# VPAC0_CP_INTD_CFG_INTD_CFG register map
Vendor: Texas Instruments
Registers are 32-bit, access not given, reset 0x0 unless marked. A register's access mark holds for its fields unless they carry their own. Offsets are as the file gives them; [hi:lo] are bit positions; {n}, {i} and the like mark numbered series.

## VPAC0_CP_INTD_CFG_INTD_CFG (part 2 of 2)
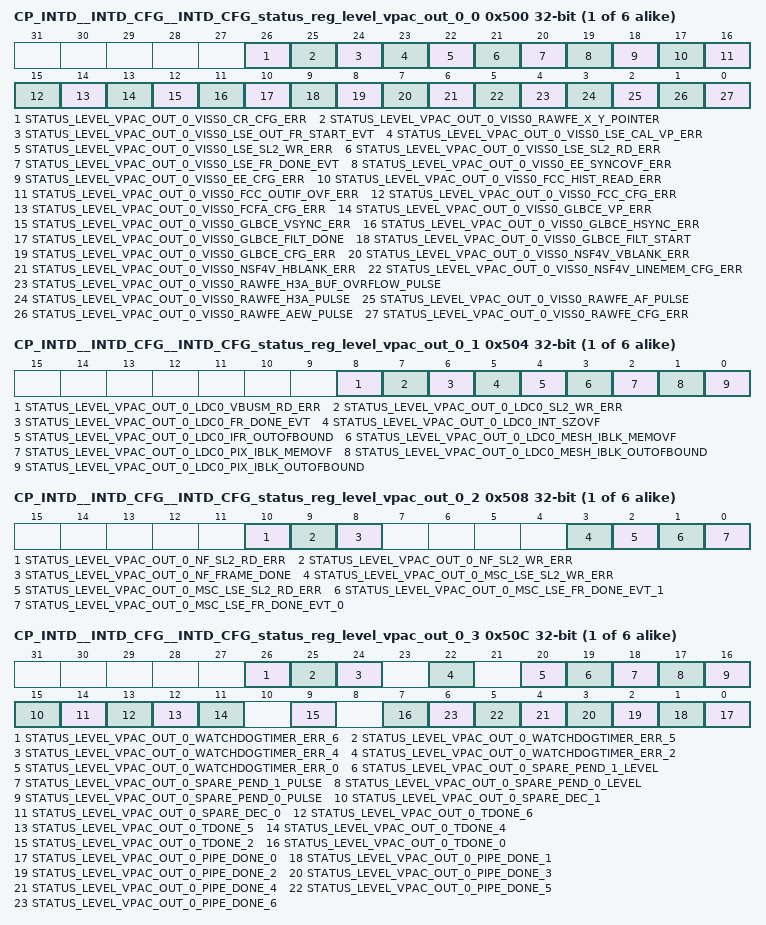
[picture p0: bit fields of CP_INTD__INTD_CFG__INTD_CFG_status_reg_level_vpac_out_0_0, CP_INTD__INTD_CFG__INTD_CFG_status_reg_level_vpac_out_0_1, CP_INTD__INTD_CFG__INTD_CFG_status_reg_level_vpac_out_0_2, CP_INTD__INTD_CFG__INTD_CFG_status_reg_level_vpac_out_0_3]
{0x500+0x20*i} CP_INTD__INTD_CFG__INTD_CFG_status_reg_level_vpac_out_{i}_0 (i=0..5) — Status Register {8i}
  [26] STATUS_LEVEL_VPAC_OUT_{i}_VISS0_CR_CFG_ERR — Status ,write 1 to set, for level_vpac_out_{i}_en_viss0_cr_cfg_err (access R/W1TS)
  [25] STATUS_LEVEL_VPAC_OUT_{i}_VISS0_RAWFE_X_Y_POINTER — Status ,write 1 to set, for level_vpac_out_{i}_en_viss0_rawfe_x_y_pointer (access R/W1TS)
  [24] STATUS_LEVEL_VPAC_OUT_{i}_VISS0_LSE_OUT_FR_START_EVT — Status ,write 1 to set, for level_vpac_out_{i}_en_viss0_lse_out_fr_start_evt (access R/W1TS)
  [23] STATUS_LEVEL_VPAC_OUT_{i}_VISS0_LSE_CAL_VP_ERR — Status ,write 1 to set, for level_vpac_out_{i}_en_viss0_lse_cal_vp_err (access R/W1TS)
  [22] STATUS_LEVEL_VPAC_OUT_{i}_VISS0_LSE_SL2_WR_ERR — Status ,write 1 to set, for level_vpac_out_{i}_en_viss0_lse_sl2_wr_err (access R/W1TS)
  [21] STATUS_LEVEL_VPAC_OUT_{i}_VISS0_LSE_SL2_RD_ERR — Status ,write 1 to set, for level_vpac_out_{i}_en_viss0_lse_sl2_rd_err (access R/W1TS)
  [20] STATUS_LEVEL_VPAC_OUT_{i}_VISS0_LSE_FR_DONE_EVT — Status ,write 1 to set, for level_vpac_out_{i}_en_viss0_lse_fr_done_evt (access R/W1TS)
  [19] STATUS_LEVEL_VPAC_OUT_{i}_VISS0_EE_SYNCOVF_ERR — Status ,write 1 to set, for level_vpac_out_{i}_en_viss0_ee_syncovf_err (access R/W1TS)
  [18] STATUS_LEVEL_VPAC_OUT_{i}_VISS0_EE_CFG_ERR — Status ,write 1 to set, for level_vpac_out_{i}_en_viss0_ee_cfg_err (access R/W1TS)
  [17] STATUS_LEVEL_VPAC_OUT_{i}_VISS0_FCC_HIST_READ_ERR — Status ,write 1 to set, for level_vpac_out_{i}_en_viss0_fcc_hist_read_err (access R/W1TS)
  [16] STATUS_LEVEL_VPAC_OUT_{i}_VISS0_FCC_OUTIF_OVF_ERR — Status ,write 1 to set, for level_vpac_out_{i}_en_viss0_fcc_outif_ovf_err (access R/W1TS)
  [15] STATUS_LEVEL_VPAC_OUT_{i}_VISS0_FCC_CFG_ERR — Status ,write 1 to set, for level_vpac_out_{i}_en_viss0_fcc_cfg_err (access R/W1TS)
  [14] STATUS_LEVEL_VPAC_OUT_{i}_VISS0_FCFA_CFG_ERR — Status ,write 1 to set, for level_vpac_out_{i}_en_viss0_fcfa_cfg_err (access R/W1TS)
  [13] STATUS_LEVEL_VPAC_OUT_{i}_VISS0_GLBCE_VP_ERR — Status ,write 1 to set, for level_vpac_out_{i}_en_viss0_glbce_vp_err (access R/W1TS)
  [12] STATUS_LEVEL_VPAC_OUT_{i}_VISS0_GLBCE_VSYNC_ERR — Status ,write 1 to set, for level_vpac_out_{i}_en_viss0_glbce_vsync_err (access R/W1TS)
  [11] STATUS_LEVEL_VPAC_OUT_{i}_VISS0_GLBCE_HSYNC_ERR — Status ,write 1 to set, for level_vpac_out_{i}_en_viss0_glbce_hsync_err (access R/W1TS)
  [10] STATUS_LEVEL_VPAC_OUT_{i}_VISS0_GLBCE_FILT_DONE — Status ,write 1 to set, for level_vpac_out_{i}_en_viss0_glbce_filt_done (access R/W1TS)
  [9] STATUS_LEVEL_VPAC_OUT_{i}_VISS0_GLBCE_FILT_START — Status ,write 1 to set, for level_vpac_out_{i}_en_viss0_glbce_filt_start (access R/W1TS)
  [8] STATUS_LEVEL_VPAC_OUT_{i}_VISS0_GLBCE_CFG_ERR — Status ,write 1 to set, for level_vpac_out_{i}_en_viss0_glbce_cfg_err (access R/W1TS)
  [7] STATUS_LEVEL_VPAC_OUT_{i}_VISS0_NSF4V_VBLANK_ERR — Status ,write 1 to set, for level_vpac_out_{i}_en_viss0_nsf4v_vblank_err (access R/W1TS)
  [6] STATUS_LEVEL_VPAC_OUT_{i}_VISS0_NSF4V_HBLANK_ERR — Status ,write 1 to set, for level_vpac_out_{i}_en_viss0_nsf4v_hblank_err (access R/W1TS)
  [5] STATUS_LEVEL_VPAC_OUT_{i}_VISS0_NSF4V_LINEMEM_CFG_ERR — Status ,write 1 to set, for level_vpac_out_{i}_en_viss0_nsf4v_linemem_cfg_err (access R/W1TS)
  [4] STATUS_LEVEL_VPAC_OUT_{i}_VISS0_RAWFE_H3A_BUF_OVRFLOW_PULSE — Status ,write 1 to set, for level_vpac_out_{i}_en_viss0_rawfe_h3a_buf_ovrflow_pulse (access R/W1TS)
  [3] STATUS_LEVEL_VPAC_OUT_{i}_VISS0_RAWFE_H3A_PULSE — Status ,write 1 to set, for level_vpac_out_{i}_en_viss0_rawfe_h3a_pulse (access R/W1TS)
  [2] STATUS_LEVEL_VPAC_OUT_{i}_VISS0_RAWFE_AF_PULSE — Status ,write 1 to set, for level_vpac_out_{i}_en_viss0_rawfe_af_pulse (access R/W1TS)
  [1] STATUS_LEVEL_VPAC_OUT_{i}_VISS0_RAWFE_AEW_PULSE — Status ,write 1 to set, for level_vpac_out_{i}_en_viss0_rawfe_aew_pulse (access R/W1TS)
  [0] STATUS_LEVEL_VPAC_OUT_{i}_VISS0_RAWFE_CFG_ERR — Status ,write 1 to set, for level_vpac_out_{i}_en_viss0_rawfe_cfg_err (access R/W1TS)
{0x504+0x20*i} CP_INTD__INTD_CFG__INTD_CFG_status_reg_level_vpac_out_{i}_1 (i=0..5) — Status Register {8i+1}
  [8] STATUS_LEVEL_VPAC_OUT_{i}_LDC0_VBUSM_RD_ERR — Status ,write 1 to set, for level_vpac_out_{i}_en_ldc0_vbusm_rd_err (access R/W1TS)
  [7] STATUS_LEVEL_VPAC_OUT_{i}_LDC0_SL2_WR_ERR — Status ,write 1 to set, for level_vpac_out_{i}_en_ldc0_sl2_wr_err (access R/W1TS)
  [6] STATUS_LEVEL_VPAC_OUT_{i}_LDC0_FR_DONE_EVT — Status ,write 1 to set, for level_vpac_out_{i}_en_ldc0_fr_done_evt (access R/W1TS)
  [5] STATUS_LEVEL_VPAC_OUT_{i}_LDC0_INT_SZOVF — Status ,write 1 to set, for level_vpac_out_{i}_en_ldc0_int_szovf (access R/W1TS)
  [4] STATUS_LEVEL_VPAC_OUT_{i}_LDC0_IFR_OUTOFBOUND — Status ,write 1 to set, for level_vpac_out_{i}_en_ldc0_ifr_outofbound (access R/W1TS)
  [3] STATUS_LEVEL_VPAC_OUT_{i}_LDC0_MESH_IBLK_MEMOVF — Status ,write 1 to set, for level_vpac_out_{i}_en_ldc0_mesh_iblk_memovf (access R/W1TS)
  [2] STATUS_LEVEL_VPAC_OUT_{i}_LDC0_PIX_IBLK_MEMOVF — Status ,write 1 to set, for level_vpac_out_{i}_en_ldc0_pix_iblk_memovf (access R/W1TS)
  [1] STATUS_LEVEL_VPAC_OUT_{i}_LDC0_MESH_IBLK_OUTOFBOUND — Status ,write 1 to set, for level_vpac_out_{i}_en_ldc0_mesh_iblk_outofbound (access R/W1TS)
  [0] STATUS_LEVEL_VPAC_OUT_{i}_LDC0_PIX_IBLK_OUTOFBOUND — Status ,write 1 to set, for level_vpac_out_{i}_en_ldc0_pix_iblk_outofbound (access R/W1TS)
{0x508+0x20*i} CP_INTD__INTD_CFG__INTD_CFG_status_reg_level_vpac_out_{i}_2 (i=0..5) — Status Register {8i+2}
  [10] STATUS_LEVEL_VPAC_OUT_{i}_NF_SL2_RD_ERR — Status ,write 1 to set, for level_vpac_out_{i}_en_nf_sl2_rd_err (access R/W1TS)
  [9] STATUS_LEVEL_VPAC_OUT_{i}_NF_SL2_WR_ERR — Status ,write 1 to set, for level_vpac_out_{i}_en_nf_sl2_wr_err (access R/W1TS)
  [8] STATUS_LEVEL_VPAC_OUT_{i}_NF_FRAME_DONE — Status ,write 1 to set, for level_vpac_out_{i}_en_nf_frame_done (access R/W1TS)
  [3] STATUS_LEVEL_VPAC_OUT_{i}_MSC_LSE_SL2_WR_ERR — Status ,write 1 to set, for level_vpac_out_{i}_en_msc_lse_sl2_wr_err (access R/W1TS)
  [2] STATUS_LEVEL_VPAC_OUT_{i}_MSC_LSE_SL2_RD_ERR — Status ,write 1 to set, for level_vpac_out_{i}_en_msc_lse_sl2_rd_err (access R/W1TS)
  [1] STATUS_LEVEL_VPAC_OUT_{i}_MSC_LSE_FR_DONE_EVT_1 — Status ,write 1 to set, for level_vpac_out_{i}_en_msc_lse_fr_done_evt_1 (access R/W1TS)
  [0] STATUS_LEVEL_VPAC_OUT_{i}_MSC_LSE_FR_DONE_EVT_0 — Status ,write 1 to set, for level_vpac_out_{i}_en_msc_lse_fr_done_evt_0 (access R/W1TS)
{0x50C+0x20*i} CP_INTD__INTD_CFG__INTD_CFG_status_reg_level_vpac_out_{i}_3 (i=0..5) — Status Register {8i+3}
  [26] STATUS_LEVEL_VPAC_OUT_{i}_WATCHDOGTIMER_ERR_6 — Status ,write 1 to set, for level_vpac_out_{i}_en_watchdogtimer_err_6 (access R/W1TS)
  [25] STATUS_LEVEL_VPAC_OUT_{i}_WATCHDOGTIMER_ERR_5 — Status ,write 1 to set, for level_vpac_out_{i}_en_watchdogtimer_err_5 (access R/W1TS)
  [24] STATUS_LEVEL_VPAC_OUT_{i}_WATCHDOGTIMER_ERR_4 — Status ,write 1 to set, for level_vpac_out_{i}_en_watchdogtimer_err_4 (access R/W1TS)
  [22] STATUS_LEVEL_VPAC_OUT_{i}_WATCHDOGTIMER_ERR_2 — Status ,write 1 to set, for level_vpac_out_{i}_en_watchdogtimer_err_2 (access R/W1TS)
  [20] STATUS_LEVEL_VPAC_OUT_{i}_WATCHDOGTIMER_ERR_0 — Status ,write 1 to set, for level_vpac_out_{i}_en_watchdogtimer_err_0 (access R/W1TS)
  [19] STATUS_LEVEL_VPAC_OUT_{i}_SPARE_PEND_1_LEVEL ro — Status for level_vpac_out_{i}_en_spare_pend_1_level
  [18] STATUS_LEVEL_VPAC_OUT_{i}_SPARE_PEND_1_PULSE ro — Status for level_vpac_out_{i}_en_spare_pend_1_pulse
  [17] STATUS_LEVEL_VPAC_OUT_{i}_SPARE_PEND_0_LEVEL ro — Status for level_vpac_out_{i}_en_spare_pend_0_level
  [16] STATUS_LEVEL_VPAC_OUT_{i}_SPARE_PEND_0_PULSE ro — Status for level_vpac_out_{i}_en_spare_pend_0_pulse
  [15] STATUS_LEVEL_VPAC_OUT_{i}_SPARE_DEC_1 — Status ,write 1 to set, for level_vpac_out_{i}_en_spare_dec_1 (access R/W1TS)
  [14] STATUS_LEVEL_VPAC_OUT_{i}_SPARE_DEC_0 — Status ,write 1 to set, for level_vpac_out_{i}_en_spare_dec_0 (access R/W1TS)
  [13] STATUS_LEVEL_VPAC_OUT_{i}_TDONE_6 — Status ,write 1 to set, for level_vpac_out_{i}_en_tdone_6 (access R/W1TS)
  [12] STATUS_LEVEL_VPAC_OUT_{i}_TDONE_5 — Status ,write 1 to set, for level_vpac_out_{i}_en_tdone_5 (access R/W1TS)
  [11] STATUS_LEVEL_VPAC_OUT_{i}_TDONE_4 — Status ,write 1 to set, for level_vpac_out_{i}_en_tdone_4 (access R/W1TS)
  [9] STATUS_LEVEL_VPAC_OUT_{i}_TDONE_2 — Status ,write 1 to set, for level_vpac_out_{i}_en_tdone_2 (access R/W1TS)
  [7] STATUS_LEVEL_VPAC_OUT_{i}_TDONE_0 — Status ,write 1 to set, for level_vpac_out_{i}_en_tdone_0 (access R/W1TS)
  [n] STATUS_LEVEL_VPAC_OUT_{i}_PIPE_DONE_{n} (n=0..6) — Status ,write 1 to set, for level_vpac_out_{i}_en_pipe_done_{n} (access R/W1TS)
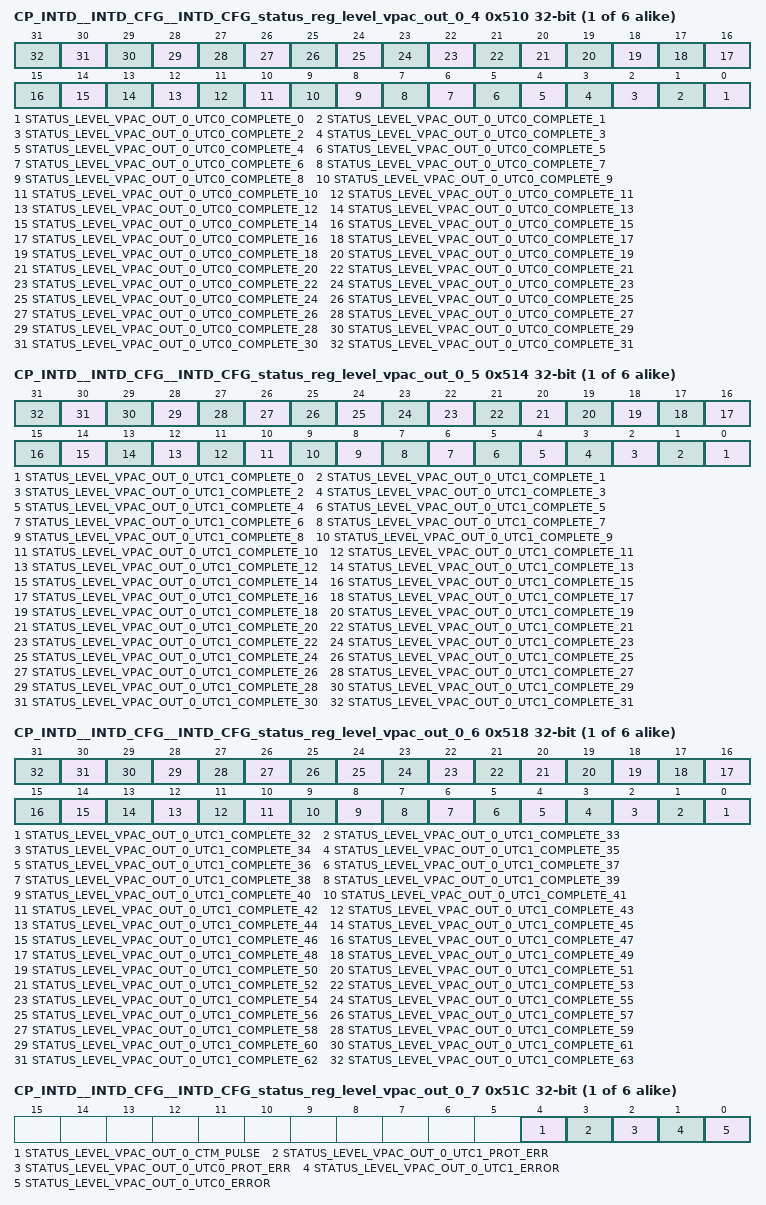
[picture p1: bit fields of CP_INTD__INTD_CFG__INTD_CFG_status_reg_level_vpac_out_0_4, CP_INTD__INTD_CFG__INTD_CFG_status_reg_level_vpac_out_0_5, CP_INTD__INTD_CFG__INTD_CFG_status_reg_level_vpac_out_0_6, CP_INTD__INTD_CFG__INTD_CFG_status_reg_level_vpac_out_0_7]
{0x510+0x20*i} CP_INTD__INTD_CFG__INTD_CFG_status_reg_level_vpac_out_{i}_4 (i=0..5) — Status Register {8i+4}
  [n] STATUS_LEVEL_VPAC_OUT_{i}_UTC0_COMPLETE_{n} (n=0..31) — Status ,write 1 to set, for level_vpac_out_{i}_en_utc0_complete_{n} (access R/W1TS)
{0x514+0x20*i} CP_INTD__INTD_CFG__INTD_CFG_status_reg_level_vpac_out_{i}_5 (i=0..5) — Status Register {8i+5}
  [n] STATUS_LEVEL_VPAC_OUT_{i}_UTC1_COMPLETE_{n} (n=0..31) — Status ,write 1 to set, for level_vpac_out_{i}_en_utc1_complete_{n} (access R/W1TS)
{0x518+0x20*i} CP_INTD__INTD_CFG__INTD_CFG_status_reg_level_vpac_out_{i}_6 (i=0..5) — Status Register {8i+6}
  [n-32] STATUS_LEVEL_VPAC_OUT_{i}_UTC1_COMPLETE_{n} (n=32..63) — Status ,write 1 to set, for level_vpac_out_{i}_en_utc1_complete_{n} (access R/W1TS)
{0x51C+0x20*i} CP_INTD__INTD_CFG__INTD_CFG_status_reg_level_vpac_out_{i}_7 (i=0..5) — Status Register {8i+7}
  [4] STATUS_LEVEL_VPAC_OUT_{i}_CTM_PULSE — Status ,write 1 to set, for level_vpac_out_{i}_en_ctm_pulse (access R/W1TS)
  [3] STATUS_LEVEL_VPAC_OUT_{i}_UTC1_PROT_ERR — Status ,write 1 to set, for level_vpac_out_{i}_en_utc1_prot_err (access R/W1TS)
  [2] STATUS_LEVEL_VPAC_OUT_{i}_UTC0_PROT_ERR — Status ,write 1 to set, for level_vpac_out_{i}_en_utc0_prot_err (access R/W1TS)
  [1] STATUS_LEVEL_VPAC_OUT_{i}_UTC1_ERROR — Status ,write 1 to set, for level_vpac_out_{i}_en_utc1_error (access R/W1TS)
  [0] STATUS_LEVEL_VPAC_OUT_{i}_UTC0_ERROR — Status ,write 1 to set, for level_vpac_out_{i}_en_utc0_error (access R/W1TS)
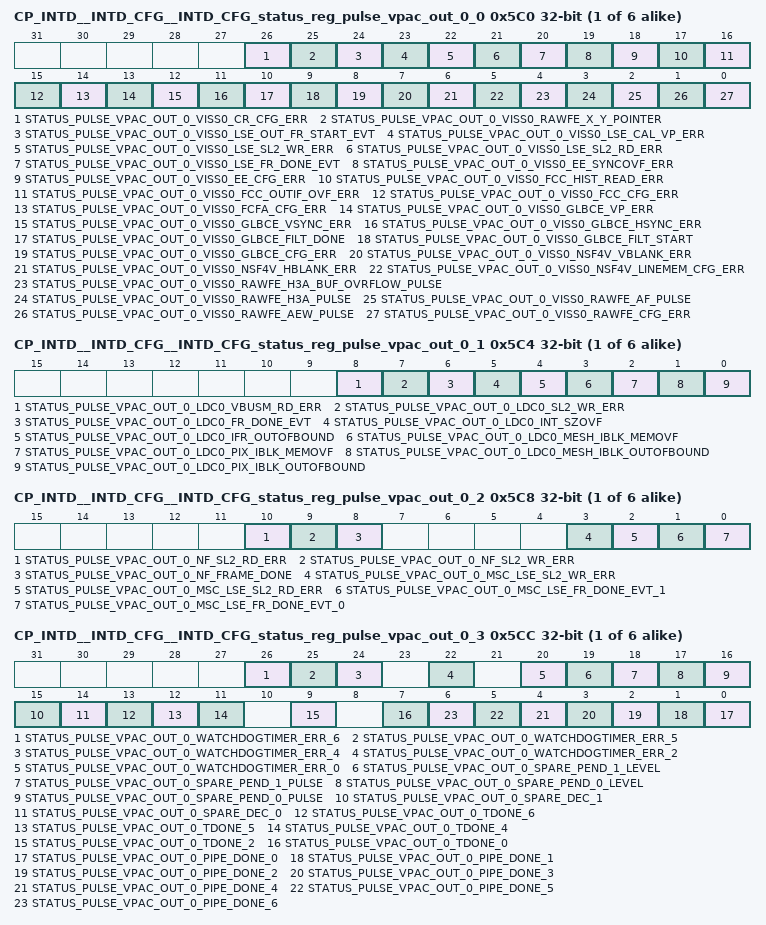
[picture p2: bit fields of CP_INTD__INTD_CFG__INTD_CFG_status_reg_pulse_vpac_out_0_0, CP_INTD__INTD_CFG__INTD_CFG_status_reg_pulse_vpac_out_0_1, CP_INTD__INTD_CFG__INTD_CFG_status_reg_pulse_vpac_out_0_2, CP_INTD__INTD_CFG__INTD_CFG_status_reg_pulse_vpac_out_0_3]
{0x5C0+0x20*i} CP_INTD__INTD_CFG__INTD_CFG_status_reg_pulse_vpac_out_{i}_0 (i=0..5) — Status Register {8i+48}
  [26] STATUS_PULSE_VPAC_OUT_{i}_VISS0_CR_CFG_ERR — Status ,write 1 to set, for pulse_vpac_out_{i}_en_viss0_cr_cfg_err (access R/W1TS)
  [25] STATUS_PULSE_VPAC_OUT_{i}_VISS0_RAWFE_X_Y_POINTER — Status ,write 1 to set, for pulse_vpac_out_{i}_en_viss0_rawfe_x_y_pointer (access R/W1TS)
  [24] STATUS_PULSE_VPAC_OUT_{i}_VISS0_LSE_OUT_FR_START_EVT — Status ,write 1 to set, for pulse_vpac_out_{i}_en_viss0_lse_out_fr_start_evt (access R/W1TS)
  [23] STATUS_PULSE_VPAC_OUT_{i}_VISS0_LSE_CAL_VP_ERR — Status ,write 1 to set, for pulse_vpac_out_{i}_en_viss0_lse_cal_vp_err (access R/W1TS)
  [22] STATUS_PULSE_VPAC_OUT_{i}_VISS0_LSE_SL2_WR_ERR — Status ,write 1 to set, for pulse_vpac_out_{i}_en_viss0_lse_sl2_wr_err (access R/W1TS)
  [21] STATUS_PULSE_VPAC_OUT_{i}_VISS0_LSE_SL2_RD_ERR — Status ,write 1 to set, for pulse_vpac_out_{i}_en_viss0_lse_sl2_rd_err (access R/W1TS)
  [20] STATUS_PULSE_VPAC_OUT_{i}_VISS0_LSE_FR_DONE_EVT — Status ,write 1 to set, for pulse_vpac_out_{i}_en_viss0_lse_fr_done_evt (access R/W1TS)
  [19] STATUS_PULSE_VPAC_OUT_{i}_VISS0_EE_SYNCOVF_ERR — Status ,write 1 to set, for pulse_vpac_out_{i}_en_viss0_ee_syncovf_err (access R/W1TS)
  [18] STATUS_PULSE_VPAC_OUT_{i}_VISS0_EE_CFG_ERR — Status ,write 1 to set, for pulse_vpac_out_{i}_en_viss0_ee_cfg_err (access R/W1TS)
  [17] STATUS_PULSE_VPAC_OUT_{i}_VISS0_FCC_HIST_READ_ERR — Status ,write 1 to set, for pulse_vpac_out_{i}_en_viss0_fcc_hist_read_err (access R/W1TS)
  [16] STATUS_PULSE_VPAC_OUT_{i}_VISS0_FCC_OUTIF_OVF_ERR — Status ,write 1 to set, for pulse_vpac_out_{i}_en_viss0_fcc_outif_ovf_err (access R/W1TS)
  [15] STATUS_PULSE_VPAC_OUT_{i}_VISS0_FCC_CFG_ERR — Status ,write 1 to set, for pulse_vpac_out_{i}_en_viss0_fcc_cfg_err (access R/W1TS)
  [14] STATUS_PULSE_VPAC_OUT_{i}_VISS0_FCFA_CFG_ERR — Status ,write 1 to set, for pulse_vpac_out_{i}_en_viss0_fcfa_cfg_err (access R/W1TS)
  [13] STATUS_PULSE_VPAC_OUT_{i}_VISS0_GLBCE_VP_ERR — Status ,write 1 to set, for pulse_vpac_out_{i}_en_viss0_glbce_vp_err (access R/W1TS)
  [12] STATUS_PULSE_VPAC_OUT_{i}_VISS0_GLBCE_VSYNC_ERR — Status ,write 1 to set, for pulse_vpac_out_{i}_en_viss0_glbce_vsync_err (access R/W1TS)
  [11] STATUS_PULSE_VPAC_OUT_{i}_VISS0_GLBCE_HSYNC_ERR — Status ,write 1 to set, for pulse_vpac_out_{i}_en_viss0_glbce_hsync_err (access R/W1TS)
  [10] STATUS_PULSE_VPAC_OUT_{i}_VISS0_GLBCE_FILT_DONE — Status ,write 1 to set, for pulse_vpac_out_{i}_en_viss0_glbce_filt_done (access R/W1TS)
  [9] STATUS_PULSE_VPAC_OUT_{i}_VISS0_GLBCE_FILT_START — Status ,write 1 to set, for pulse_vpac_out_{i}_en_viss0_glbce_filt_start (access R/W1TS)
  [8] STATUS_PULSE_VPAC_OUT_{i}_VISS0_GLBCE_CFG_ERR — Status ,write 1 to set, for pulse_vpac_out_{i}_en_viss0_glbce_cfg_err (access R/W1TS)
  [7] STATUS_PULSE_VPAC_OUT_{i}_VISS0_NSF4V_VBLANK_ERR — Status ,write 1 to set, for pulse_vpac_out_{i}_en_viss0_nsf4v_vblank_err (access R/W1TS)
  [6] STATUS_PULSE_VPAC_OUT_{i}_VISS0_NSF4V_HBLANK_ERR — Status ,write 1 to set, for pulse_vpac_out_{i}_en_viss0_nsf4v_hblank_err (access R/W1TS)
  [5] STATUS_PULSE_VPAC_OUT_{i}_VISS0_NSF4V_LINEMEM_CFG_ERR — Status ,write 1 to set, for pulse_vpac_out_{i}_en_viss0_nsf4v_linemem_cfg_err (access R/W1TS)
  [4] STATUS_PULSE_VPAC_OUT_{i}_VISS0_RAWFE_H3A_BUF_OVRFLOW_PULSE — Status ,write 1 to set, for pulse_vpac_out_{i}_en_viss0_rawfe_h3a_buf_ovrflow_pulse (access R/W1TS)
  [3] STATUS_PULSE_VPAC_OUT_{i}_VISS0_RAWFE_H3A_PULSE — Status ,write 1 to set, for pulse_vpac_out_{i}_en_viss0_rawfe_h3a_pulse (access R/W1TS)
  [2] STATUS_PULSE_VPAC_OUT_{i}_VISS0_RAWFE_AF_PULSE — Status ,write 1 to set, for pulse_vpac_out_{i}_en_viss0_rawfe_af_pulse (access R/W1TS)
  [1] STATUS_PULSE_VPAC_OUT_{i}_VISS0_RAWFE_AEW_PULSE — Status ,write 1 to set, for pulse_vpac_out_{i}_en_viss0_rawfe_aew_pulse (access R/W1TS)
  [0] STATUS_PULSE_VPAC_OUT_{i}_VISS0_RAWFE_CFG_ERR — Status ,write 1 to set, for pulse_vpac_out_{i}_en_viss0_rawfe_cfg_err (access R/W1TS)
{0x5C4+0x20*i} CP_INTD__INTD_CFG__INTD_CFG_status_reg_pulse_vpac_out_{i}_1 (i=0..5) — Status Register {8i+49}
  [8] STATUS_PULSE_VPAC_OUT_{i}_LDC0_VBUSM_RD_ERR — Status ,write 1 to set, for pulse_vpac_out_{i}_en_ldc0_vbusm_rd_err (access R/W1TS)
  [7] STATUS_PULSE_VPAC_OUT_{i}_LDC0_SL2_WR_ERR — Status ,write 1 to set, for pulse_vpac_out_{i}_en_ldc0_sl2_wr_err (access R/W1TS)
  [6] STATUS_PULSE_VPAC_OUT_{i}_LDC0_FR_DONE_EVT — Status ,write 1 to set, for pulse_vpac_out_{i}_en_ldc0_fr_done_evt (access R/W1TS)
  [5] STATUS_PULSE_VPAC_OUT_{i}_LDC0_INT_SZOVF — Status ,write 1 to set, for pulse_vpac_out_{i}_en_ldc0_int_szovf (access R/W1TS)
  [4] STATUS_PULSE_VPAC_OUT_{i}_LDC0_IFR_OUTOFBOUND — Status ,write 1 to set, for pulse_vpac_out_{i}_en_ldc0_ifr_outofbound (access R/W1TS)
  [3] STATUS_PULSE_VPAC_OUT_{i}_LDC0_MESH_IBLK_MEMOVF — Status ,write 1 to set, for pulse_vpac_out_{i}_en_ldc0_mesh_iblk_memovf (access R/W1TS)
  [2] STATUS_PULSE_VPAC_OUT_{i}_LDC0_PIX_IBLK_MEMOVF — Status ,write 1 to set, for pulse_vpac_out_{i}_en_ldc0_pix_iblk_memovf (access R/W1TS)
  [1] STATUS_PULSE_VPAC_OUT_{i}_LDC0_MESH_IBLK_OUTOFBOUND — Status ,write 1 to set, for pulse_vpac_out_{i}_en_ldc0_mesh_iblk_outofbound (access R/W1TS)
  [0] STATUS_PULSE_VPAC_OUT_{i}_LDC0_PIX_IBLK_OUTOFBOUND — Status ,write 1 to set, for pulse_vpac_out_{i}_en_ldc0_pix_iblk_outofbound (access R/W1TS)
{0x5C8+0x20*i} CP_INTD__INTD_CFG__INTD_CFG_status_reg_pulse_vpac_out_{i}_2 (i=0..5) — Status Register {8i+50}
  [10] STATUS_PULSE_VPAC_OUT_{i}_NF_SL2_RD_ERR — Status ,write 1 to set, for pulse_vpac_out_{i}_en_nf_sl2_rd_err (access R/W1TS)
  [9] STATUS_PULSE_VPAC_OUT_{i}_NF_SL2_WR_ERR — Status ,write 1 to set, for pulse_vpac_out_{i}_en_nf_sl2_wr_err (access R/W1TS)
  [8] STATUS_PULSE_VPAC_OUT_{i}_NF_FRAME_DONE — Status ,write 1 to set, for pulse_vpac_out_{i}_en_nf_frame_done (access R/W1TS)
  [3] STATUS_PULSE_VPAC_OUT_{i}_MSC_LSE_SL2_WR_ERR — Status ,write 1 to set, for pulse_vpac_out_{i}_en_msc_lse_sl2_wr_err (access R/W1TS)
  [2] STATUS_PULSE_VPAC_OUT_{i}_MSC_LSE_SL2_RD_ERR — Status ,write 1 to set, for pulse_vpac_out_{i}_en_msc_lse_sl2_rd_err (access R/W1TS)
  [1] STATUS_PULSE_VPAC_OUT_{i}_MSC_LSE_FR_DONE_EVT_1 — Status ,write 1 to set, for pulse_vpac_out_{i}_en_msc_lse_fr_done_evt_1 (access R/W1TS)
  [0] STATUS_PULSE_VPAC_OUT_{i}_MSC_LSE_FR_DONE_EVT_0 — Status ,write 1 to set, for pulse_vpac_out_{i}_en_msc_lse_fr_done_evt_0 (access R/W1TS)
{0x5CC+0x20*i} CP_INTD__INTD_CFG__INTD_CFG_status_reg_pulse_vpac_out_{i}_3 (i=0..5) — Status Register {8i+51}
  [26] STATUS_PULSE_VPAC_OUT_{i}_WATCHDOGTIMER_ERR_6 — Status ,write 1 to set, for pulse_vpac_out_{i}_en_watchdogtimer_err_6 (access R/W1TS)
  [25] STATUS_PULSE_VPAC_OUT_{i}_WATCHDOGTIMER_ERR_5 — Status ,write 1 to set, for pulse_vpac_out_{i}_en_watchdogtimer_err_5 (access R/W1TS)
  [24] STATUS_PULSE_VPAC_OUT_{i}_WATCHDOGTIMER_ERR_4 — Status ,write 1 to set, for pulse_vpac_out_{i}_en_watchdogtimer_err_4 (access R/W1TS)
  [22] STATUS_PULSE_VPAC_OUT_{i}_WATCHDOGTIMER_ERR_2 — Status ,write 1 to set, for pulse_vpac_out_{i}_en_watchdogtimer_err_2 (access R/W1TS)
  [20] STATUS_PULSE_VPAC_OUT_{i}_WATCHDOGTIMER_ERR_0 — Status ,write 1 to set, for pulse_vpac_out_{i}_en_watchdogtimer_err_0 (access R/W1TS)
  [19] STATUS_PULSE_VPAC_OUT_{i}_SPARE_PEND_1_LEVEL ro — Status for pulse_vpac_out_{i}_en_spare_pend_1_level
  [18] STATUS_PULSE_VPAC_OUT_{i}_SPARE_PEND_1_PULSE ro — Status for pulse_vpac_out_{i}_en_spare_pend_1_pulse
  [17] STATUS_PULSE_VPAC_OUT_{i}_SPARE_PEND_0_LEVEL ro — Status for pulse_vpac_out_{i}_en_spare_pend_0_level
  [16] STATUS_PULSE_VPAC_OUT_{i}_SPARE_PEND_0_PULSE ro — Status for pulse_vpac_out_{i}_en_spare_pend_0_pulse
  [15] STATUS_PULSE_VPAC_OUT_{i}_SPARE_DEC_1 — Status ,write 1 to set, for pulse_vpac_out_{i}_en_spare_dec_1 (access R/W1TS)
  [14] STATUS_PULSE_VPAC_OUT_{i}_SPARE_DEC_0 — Status ,write 1 to set, for pulse_vpac_out_{i}_en_spare_dec_0 (access R/W1TS)
  [13] STATUS_PULSE_VPAC_OUT_{i}_TDONE_6 — Status ,write 1 to set, for pulse_vpac_out_{i}_en_tdone_6 (access R/W1TS)
  [12] STATUS_PULSE_VPAC_OUT_{i}_TDONE_5 — Status ,write 1 to set, for pulse_vpac_out_{i}_en_tdone_5 (access R/W1TS)
  [11] STATUS_PULSE_VPAC_OUT_{i}_TDONE_4 — Status ,write 1 to set, for pulse_vpac_out_{i}_en_tdone_4 (access R/W1TS)
  [9] STATUS_PULSE_VPAC_OUT_{i}_TDONE_2 — Status ,write 1 to set, for pulse_vpac_out_{i}_en_tdone_2 (access R/W1TS)
  [7] STATUS_PULSE_VPAC_OUT_{i}_TDONE_0 — Status ,write 1 to set, for pulse_vpac_out_{i}_en_tdone_0 (access R/W1TS)
  [n] STATUS_PULSE_VPAC_OUT_{i}_PIPE_DONE_{n} (n=0..6) — Status ,write 1 to set, for pulse_vpac_out_{i}_en_pipe_done_{n} (access R/W1TS)
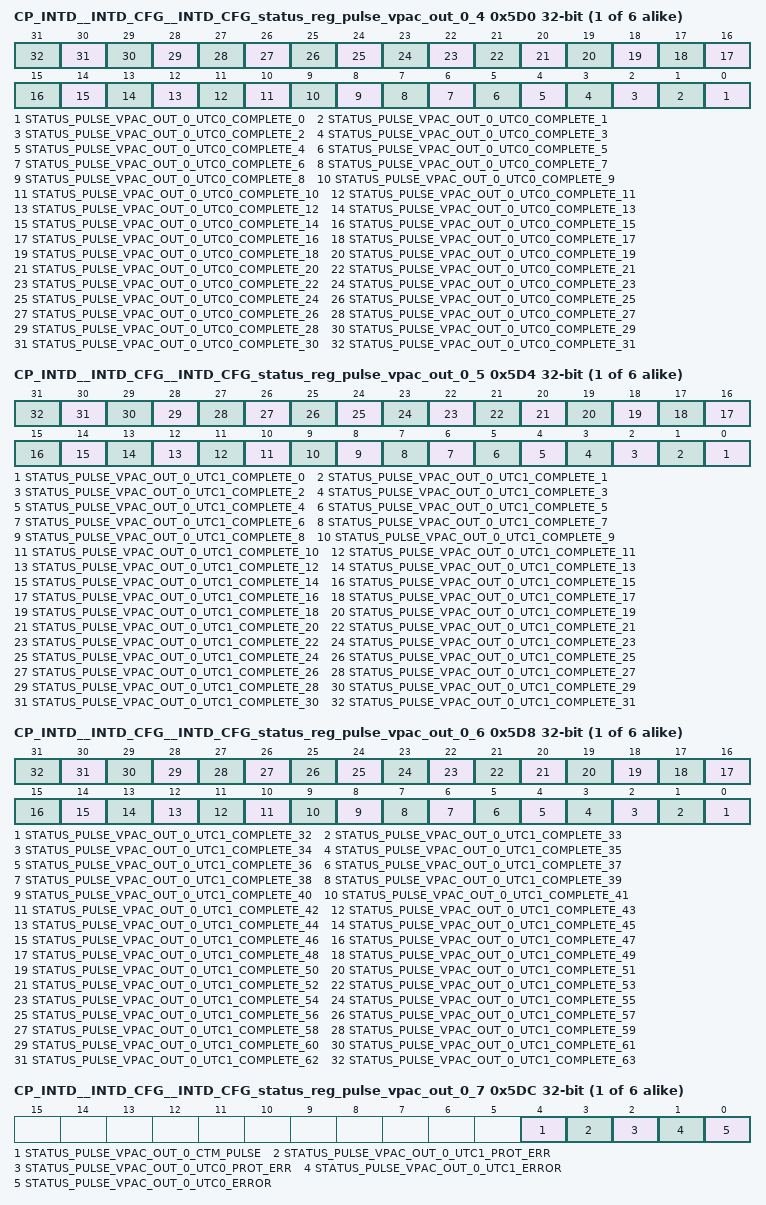
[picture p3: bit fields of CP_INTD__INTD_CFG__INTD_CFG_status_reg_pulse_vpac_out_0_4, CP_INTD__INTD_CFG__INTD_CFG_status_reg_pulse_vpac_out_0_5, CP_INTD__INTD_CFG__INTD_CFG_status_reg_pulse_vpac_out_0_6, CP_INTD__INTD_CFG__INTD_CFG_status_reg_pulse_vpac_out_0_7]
{0x5D0+0x20*i} CP_INTD__INTD_CFG__INTD_CFG_status_reg_pulse_vpac_out_{i}_4 (i=0..5) — Status Register {8i+52}
  [n] STATUS_PULSE_VPAC_OUT_{i}_UTC0_COMPLETE_{n} (n=0..31) — Status ,write 1 to set, for pulse_vpac_out_{i}_en_utc0_complete_{n} (access R/W1TS)
{0x5D4+0x20*i} CP_INTD__INTD_CFG__INTD_CFG_status_reg_pulse_vpac_out_{i}_5 (i=0..5) — Status Register {8i+53}
  [n] STATUS_PULSE_VPAC_OUT_{i}_UTC1_COMPLETE_{n} (n=0..31) — Status ,write 1 to set, for pulse_vpac_out_{i}_en_utc1_complete_{n} (access R/W1TS)
{0x5D8+0x20*i} CP_INTD__INTD_CFG__INTD_CFG_status_reg_pulse_vpac_out_{i}_6 (i=0..5) — Status Register {8i+54}
  [n-32] STATUS_PULSE_VPAC_OUT_{i}_UTC1_COMPLETE_{n} (n=32..63) — Status ,write 1 to set, for pulse_vpac_out_{i}_en_utc1_complete_{n} (access R/W1TS)
{0x5DC+0x20*i} CP_INTD__INTD_CFG__INTD_CFG_status_reg_pulse_vpac_out_{i}_7 (i=0..5) — Status Register {8i+55}
  [4] STATUS_PULSE_VPAC_OUT_{i}_CTM_PULSE — Status ,write 1 to set, for pulse_vpac_out_{i}_en_ctm_pulse (access R/W1TS)
  [3] STATUS_PULSE_VPAC_OUT_{i}_UTC1_PROT_ERR — Status ,write 1 to set, for pulse_vpac_out_{i}_en_utc1_prot_err (access R/W1TS)
  [2] STATUS_PULSE_VPAC_OUT_{i}_UTC0_PROT_ERR — Status ,write 1 to set, for pulse_vpac_out_{i}_en_utc0_prot_err (access R/W1TS)
  [1] STATUS_PULSE_VPAC_OUT_{i}_UTC1_ERROR — Status ,write 1 to set, for pulse_vpac_out_{i}_en_utc1_error (access R/W1TS)
  [0] STATUS_PULSE_VPAC_OUT_{i}_UTC0_ERROR — Status ,write 1 to set, for pulse_vpac_out_{i}_en_utc0_error (access R/W1TS)
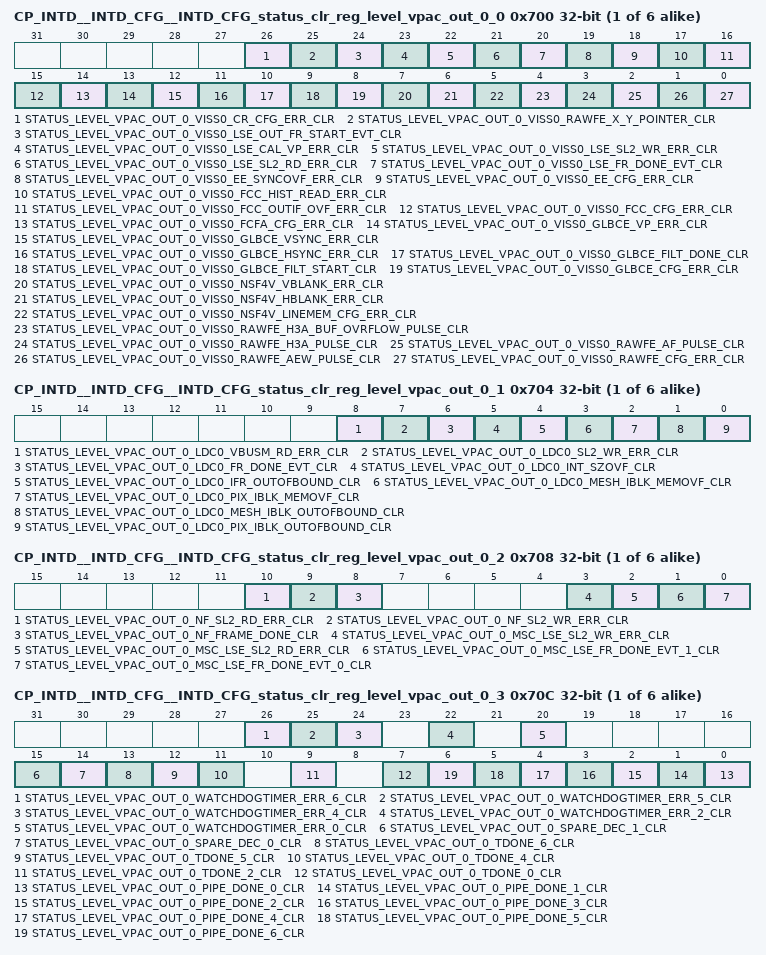
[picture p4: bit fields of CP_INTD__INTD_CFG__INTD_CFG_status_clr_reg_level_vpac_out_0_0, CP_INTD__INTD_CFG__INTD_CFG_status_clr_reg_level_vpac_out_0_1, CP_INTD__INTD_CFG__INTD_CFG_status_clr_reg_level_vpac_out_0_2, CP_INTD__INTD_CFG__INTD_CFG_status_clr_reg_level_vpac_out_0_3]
{0x700+0x20*i} CP_INTD__INTD_CFG__INTD_CFG_status_clr_reg_level_vpac_out_{i}_0 (i=0..5) — Status Clear Register {8i}
  [26] STATUS_LEVEL_VPAC_OUT_{i}_VISS0_CR_CFG_ERR_CLR — Status ,write 1 to clear, for level_vpac_out_{i}_en_viss0_cr_cfg_err (access R/W1TC)
  [25] STATUS_LEVEL_VPAC_OUT_{i}_VISS0_RAWFE_X_Y_POINTER_CLR — Status ,write 1 to clear, for level_vpac_out_{i}_en_viss0_rawfe_x_y_pointer (access R/W1TC)
  [24] STATUS_LEVEL_VPAC_OUT_{i}_VISS0_LSE_OUT_FR_START_EVT_CLR — Status ,write 1 to clear, for level_vpac_out_{i}_en_viss0_lse_out_fr_start_evt (access R/W1TC)
  [23] STATUS_LEVEL_VPAC_OUT_{i}_VISS0_LSE_CAL_VP_ERR_CLR — Status ,write 1 to clear, for level_vpac_out_{i}_en_viss0_lse_cal_vp_err (access R/W1TC)
  [22] STATUS_LEVEL_VPAC_OUT_{i}_VISS0_LSE_SL2_WR_ERR_CLR — Status ,write 1 to clear, for level_vpac_out_{i}_en_viss0_lse_sl2_wr_err (access R/W1TC)
  [21] STATUS_LEVEL_VPAC_OUT_{i}_VISS0_LSE_SL2_RD_ERR_CLR — Status ,write 1 to clear, for level_vpac_out_{i}_en_viss0_lse_sl2_rd_err (access R/W1TC)
  [20] STATUS_LEVEL_VPAC_OUT_{i}_VISS0_LSE_FR_DONE_EVT_CLR — Status ,write 1 to clear, for level_vpac_out_{i}_en_viss0_lse_fr_done_evt (access R/W1TC)
  [19] STATUS_LEVEL_VPAC_OUT_{i}_VISS0_EE_SYNCOVF_ERR_CLR — Status ,write 1 to clear, for level_vpac_out_{i}_en_viss0_ee_syncovf_err (access R/W1TC)
  [18] STATUS_LEVEL_VPAC_OUT_{i}_VISS0_EE_CFG_ERR_CLR — Status ,write 1 to clear, for level_vpac_out_{i}_en_viss0_ee_cfg_err (access R/W1TC)
  [17] STATUS_LEVEL_VPAC_OUT_{i}_VISS0_FCC_HIST_READ_ERR_CLR — Status ,write 1 to clear, for level_vpac_out_{i}_en_viss0_fcc_hist_read_err (access R/W1TC)
  [16] STATUS_LEVEL_VPAC_OUT_{i}_VISS0_FCC_OUTIF_OVF_ERR_CLR — Status ,write 1 to clear, for level_vpac_out_{i}_en_viss0_fcc_outif_ovf_err (access R/W1TC)
  [15] STATUS_LEVEL_VPAC_OUT_{i}_VISS0_FCC_CFG_ERR_CLR — Status ,write 1 to clear, for level_vpac_out_{i}_en_viss0_fcc_cfg_err (access R/W1TC)
  [14] STATUS_LEVEL_VPAC_OUT_{i}_VISS0_FCFA_CFG_ERR_CLR — Status ,write 1 to clear, for level_vpac_out_{i}_en_viss0_fcfa_cfg_err (access R/W1TC)
  [13] STATUS_LEVEL_VPAC_OUT_{i}_VISS0_GLBCE_VP_ERR_CLR — Status ,write 1 to clear, for level_vpac_out_{i}_en_viss0_glbce_vp_err (access R/W1TC)
  [12] STATUS_LEVEL_VPAC_OUT_{i}_VISS0_GLBCE_VSYNC_ERR_CLR — Status ,write 1 to clear, for level_vpac_out_{i}_en_viss0_glbce_vsync_err (access R/W1TC)
  [11] STATUS_LEVEL_VPAC_OUT_{i}_VISS0_GLBCE_HSYNC_ERR_CLR — Status ,write 1 to clear, for level_vpac_out_{i}_en_viss0_glbce_hsync_err (access R/W1TC)
  [10] STATUS_LEVEL_VPAC_OUT_{i}_VISS0_GLBCE_FILT_DONE_CLR — Status ,write 1 to clear, for level_vpac_out_{i}_en_viss0_glbce_filt_done (access R/W1TC)
  [9] STATUS_LEVEL_VPAC_OUT_{i}_VISS0_GLBCE_FILT_START_CLR — Status ,write 1 to clear, for level_vpac_out_{i}_en_viss0_glbce_filt_start (access R/W1TC)
  [8] STATUS_LEVEL_VPAC_OUT_{i}_VISS0_GLBCE_CFG_ERR_CLR — Status ,write 1 to clear, for level_vpac_out_{i}_en_viss0_glbce_cfg_err (access R/W1TC)
  [7] STATUS_LEVEL_VPAC_OUT_{i}_VISS0_NSF4V_VBLANK_ERR_CLR — Status ,write 1 to clear, for level_vpac_out_{i}_en_viss0_nsf4v_vblank_err (access R/W1TC)
  [6] STATUS_LEVEL_VPAC_OUT_{i}_VISS0_NSF4V_HBLANK_ERR_CLR — Status ,write 1 to clear, for level_vpac_out_{i}_en_viss0_nsf4v_hblank_err (access R/W1TC)
  [5] STATUS_LEVEL_VPAC_OUT_{i}_VISS0_NSF4V_LINEMEM_CFG_ERR_CLR — Status ,write 1 to clear, for level_vpac_out_{i}_en_viss0_nsf4v_linemem_cfg_err (access R/W1TC)
  [4] STATUS_LEVEL_VPAC_OUT_{i}_VISS0_RAWFE_H3A_BUF_OVRFLOW_PULSE_CLR — Status ,write 1 to clear, for level_vpac_out_{i}_en_viss0_rawfe_h3a_buf_ovrflow_pulse (access R/W1TC)
  [3] STATUS_LEVEL_VPAC_OUT_{i}_VISS0_RAWFE_H3A_PULSE_CLR — Status ,write 1 to clear, for level_vpac_out_{i}_en_viss0_rawfe_h3a_pulse (access R/W1TC)
  [2] STATUS_LEVEL_VPAC_OUT_{i}_VISS0_RAWFE_AF_PULSE_CLR — Status ,write 1 to clear, for level_vpac_out_{i}_en_viss0_rawfe_af_pulse (access R/W1TC)
  [1] STATUS_LEVEL_VPAC_OUT_{i}_VISS0_RAWFE_AEW_PULSE_CLR — Status ,write 1 to clear, for level_vpac_out_{i}_en_viss0_rawfe_aew_pulse (access R/W1TC)
  [0] STATUS_LEVEL_VPAC_OUT_{i}_VISS0_RAWFE_CFG_ERR_CLR — Status ,write 1 to clear, for level_vpac_out_{i}_en_viss0_rawfe_cfg_err (access R/W1TC)
{0x704+0x20*i} CP_INTD__INTD_CFG__INTD_CFG_status_clr_reg_level_vpac_out_{i}_1 (i=0..5) — Status Clear Register {8i+1}
  [8] STATUS_LEVEL_VPAC_OUT_{i}_LDC0_VBUSM_RD_ERR_CLR — Status ,write 1 to clear, for level_vpac_out_{i}_en_ldc0_vbusm_rd_err (access R/W1TC)
  [7] STATUS_LEVEL_VPAC_OUT_{i}_LDC0_SL2_WR_ERR_CLR — Status ,write 1 to clear, for level_vpac_out_{i}_en_ldc0_sl2_wr_err (access R/W1TC)
  [6] STATUS_LEVEL_VPAC_OUT_{i}_LDC0_FR_DONE_EVT_CLR — Status ,write 1 to clear, for level_vpac_out_{i}_en_ldc0_fr_done_evt (access R/W1TC)
  [5] STATUS_LEVEL_VPAC_OUT_{i}_LDC0_INT_SZOVF_CLR — Status ,write 1 to clear, for level_vpac_out_{i}_en_ldc0_int_szovf (access R/W1TC)
  [4] STATUS_LEVEL_VPAC_OUT_{i}_LDC0_IFR_OUTOFBOUND_CLR — Status ,write 1 to clear, for level_vpac_out_{i}_en_ldc0_ifr_outofbound (access R/W1TC)
  [3] STATUS_LEVEL_VPAC_OUT_{i}_LDC0_MESH_IBLK_MEMOVF_CLR — Status ,write 1 to clear, for level_vpac_out_{i}_en_ldc0_mesh_iblk_memovf (access R/W1TC)
  [2] STATUS_LEVEL_VPAC_OUT_{i}_LDC0_PIX_IBLK_MEMOVF_CLR — Status ,write 1 to clear, for level_vpac_out_{i}_en_ldc0_pix_iblk_memovf (access R/W1TC)
  [1] STATUS_LEVEL_VPAC_OUT_{i}_LDC0_MESH_IBLK_OUTOFBOUND_CLR — Status ,write 1 to clear, for level_vpac_out_{i}_en_ldc0_mesh_iblk_outofbound (access R/W1TC)
  [0] STATUS_LEVEL_VPAC_OUT_{i}_LDC0_PIX_IBLK_OUTOFBOUND_CLR — Status ,write 1 to clear, for level_vpac_out_{i}_en_ldc0_pix_iblk_outofbound (access R/W1TC)
{0x708+0x20*i} CP_INTD__INTD_CFG__INTD_CFG_status_clr_reg_level_vpac_out_{i}_2 (i=0..5) — Status Clear Register {8i+2}
  [10] STATUS_LEVEL_VPAC_OUT_{i}_NF_SL2_RD_ERR_CLR — Status ,write 1 to clear, for level_vpac_out_{i}_en_nf_sl2_rd_err (access R/W1TC)
  [9] STATUS_LEVEL_VPAC_OUT_{i}_NF_SL2_WR_ERR_CLR — Status ,write 1 to clear, for level_vpac_out_{i}_en_nf_sl2_wr_err (access R/W1TC)
  [8] STATUS_LEVEL_VPAC_OUT_{i}_NF_FRAME_DONE_CLR — Status ,write 1 to clear, for level_vpac_out_{i}_en_nf_frame_done (access R/W1TC)
  [3] STATUS_LEVEL_VPAC_OUT_{i}_MSC_LSE_SL2_WR_ERR_CLR — Status ,write 1 to clear, for level_vpac_out_{i}_en_msc_lse_sl2_wr_err (access R/W1TC)
  [2] STATUS_LEVEL_VPAC_OUT_{i}_MSC_LSE_SL2_RD_ERR_CLR — Status ,write 1 to clear, for level_vpac_out_{i}_en_msc_lse_sl2_rd_err (access R/W1TC)
  [1] STATUS_LEVEL_VPAC_OUT_{i}_MSC_LSE_FR_DONE_EVT_1_CLR — Status ,write 1 to clear, for level_vpac_out_{i}_en_msc_lse_fr_done_evt_1 (access R/W1TC)
  [0] STATUS_LEVEL_VPAC_OUT_{i}_MSC_LSE_FR_DONE_EVT_0_CLR — Status ,write 1 to clear, for level_vpac_out_{i}_en_msc_lse_fr_done_evt_0 (access R/W1TC)
{0x70C+0x20*i} CP_INTD__INTD_CFG__INTD_CFG_status_clr_reg_level_vpac_out_{i}_3 (i=0..5) — Status Clear Register {8i+3}
  [26] STATUS_LEVEL_VPAC_OUT_{i}_WATCHDOGTIMER_ERR_6_CLR — Status ,write 1 to clear, for level_vpac_out_{i}_en_watchdogtimer_err_6 (access R/W1TC)
  [25] STATUS_LEVEL_VPAC_OUT_{i}_WATCHDOGTIMER_ERR_5_CLR — Status ,write 1 to clear, for level_vpac_out_{i}_en_watchdogtimer_err_5 (access R/W1TC)
  [24] STATUS_LEVEL_VPAC_OUT_{i}_WATCHDOGTIMER_ERR_4_CLR — Status ,write 1 to clear, for level_vpac_out_{i}_en_watchdogtimer_err_4 (access R/W1TC)
  [22] STATUS_LEVEL_VPAC_OUT_{i}_WATCHDOGTIMER_ERR_2_CLR — Status ,write 1 to clear, for level_vpac_out_{i}_en_watchdogtimer_err_2 (access R/W1TC)
  [20] STATUS_LEVEL_VPAC_OUT_{i}_WATCHDOGTIMER_ERR_0_CLR — Status ,write 1 to clear, for level_vpac_out_{i}_en_watchdogtimer_err_0 (access R/W1TC)
  [15] STATUS_LEVEL_VPAC_OUT_{i}_SPARE_DEC_1_CLR — Status ,write 1 to clear, for level_vpac_out_{i}_en_spare_dec_1 (access R/W1TC)
  [14] STATUS_LEVEL_VPAC_OUT_{i}_SPARE_DEC_0_CLR — Status ,write 1 to clear, for level_vpac_out_{i}_en_spare_dec_0 (access R/W1TC)
  [13] STATUS_LEVEL_VPAC_OUT_{i}_TDONE_6_CLR — Status ,write 1 to clear, for level_vpac_out_{i}_en_tdone_6 (access R/W1TC)
  [12] STATUS_LEVEL_VPAC_OUT_{i}_TDONE_5_CLR — Status ,write 1 to clear, for level_vpac_out_{i}_en_tdone_5 (access R/W1TC)
  [11] STATUS_LEVEL_VPAC_OUT_{i}_TDONE_4_CLR — Status ,write 1 to clear, for level_vpac_out_{i}_en_tdone_4 (access R/W1TC)
  [9] STATUS_LEVEL_VPAC_OUT_{i}_TDONE_2_CLR — Status ,write 1 to clear, for level_vpac_out_{i}_en_tdone_2 (access R/W1TC)
  [7] STATUS_LEVEL_VPAC_OUT_{i}_TDONE_0_CLR — Status ,write 1 to clear, for level_vpac_out_{i}_en_tdone_0 (access R/W1TC)
  [n] STATUS_LEVEL_VPAC_OUT_{i}_PIPE_DONE_{n}_CLR (n=0..6) — Status ,write 1 to clear, for level_vpac_out_{i}_en_pipe_done_{n} (access R/W1TC)
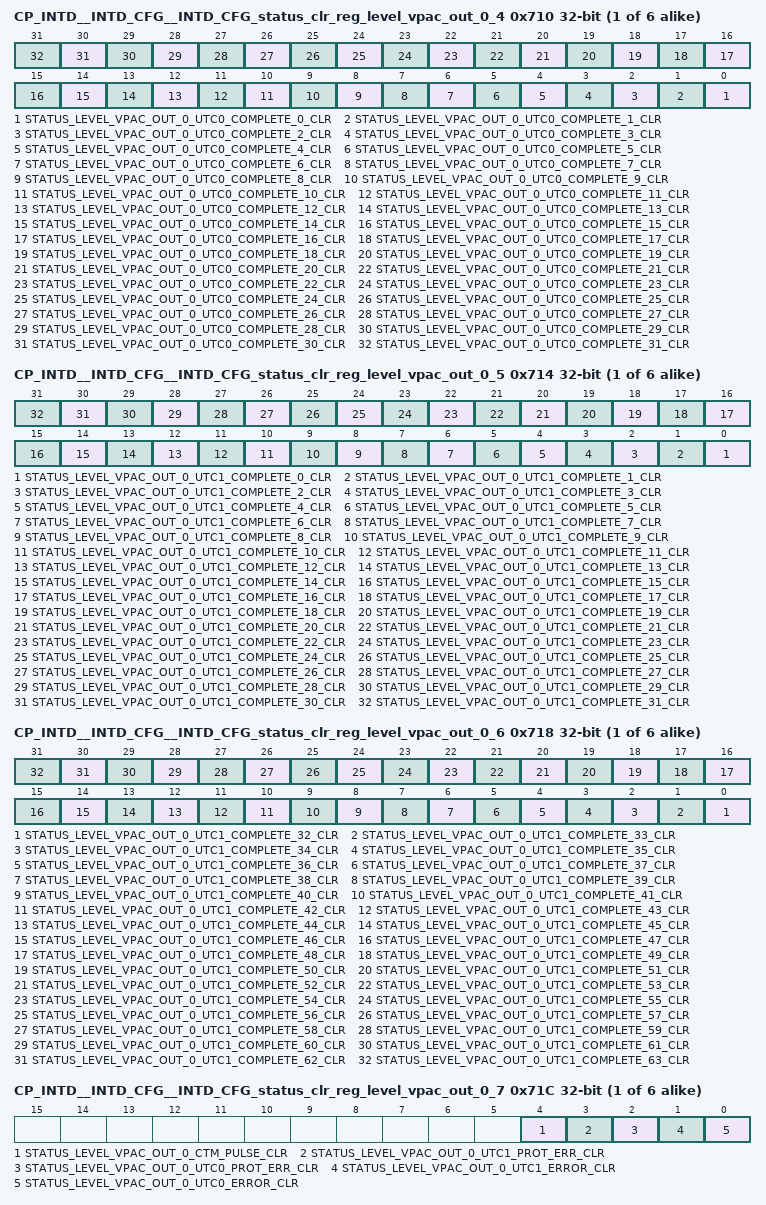
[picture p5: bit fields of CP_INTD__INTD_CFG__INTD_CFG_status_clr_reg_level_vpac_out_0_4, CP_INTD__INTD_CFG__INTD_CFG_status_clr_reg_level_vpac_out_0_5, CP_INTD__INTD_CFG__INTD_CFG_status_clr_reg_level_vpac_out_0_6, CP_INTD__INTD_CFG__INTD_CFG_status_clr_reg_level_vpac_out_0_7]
{0x710+0x20*i} CP_INTD__INTD_CFG__INTD_CFG_status_clr_reg_level_vpac_out_{i}_4 (i=0..5) — Status Clear Register {8i+4}
  [n] STATUS_LEVEL_VPAC_OUT_{i}_UTC0_COMPLETE_{n}_CLR (n=0..31) — Status ,write 1 to clear, for level_vpac_out_{i}_en_utc0_complete_{n} (access R/W1TC)
{0x714+0x20*i} CP_INTD__INTD_CFG__INTD_CFG_status_clr_reg_level_vpac_out_{i}_5 (i=0..5) — Status Clear Register {8i+5}
  [n] STATUS_LEVEL_VPAC_OUT_{i}_UTC1_COMPLETE_{n}_CLR (n=0..31) — Status ,write 1 to clear, for level_vpac_out_{i}_en_utc1_complete_{n} (access R/W1TC)
{0x718+0x20*i} CP_INTD__INTD_CFG__INTD_CFG_status_clr_reg_level_vpac_out_{i}_6 (i=0..5) — Status Clear Register {8i+6}
  [n-32] STATUS_LEVEL_VPAC_OUT_{i}_UTC1_COMPLETE_{n}_CLR (n=32..63) — Status ,write 1 to clear, for level_vpac_out_{i}_en_utc1_complete_{n} (access R/W1TC)
{0x71C+0x20*i} CP_INTD__INTD_CFG__INTD_CFG_status_clr_reg_level_vpac_out_{i}_7 (i=0..5) — Status Clear Register {8i+7}
  [4] STATUS_LEVEL_VPAC_OUT_{i}_CTM_PULSE_CLR — Status ,write 1 to clear, for level_vpac_out_{i}_en_ctm_pulse (access R/W1TC)
  [3] STATUS_LEVEL_VPAC_OUT_{i}_UTC1_PROT_ERR_CLR — Status ,write 1 to clear, for level_vpac_out_{i}_en_utc1_prot_err (access R/W1TC)
  [2] STATUS_LEVEL_VPAC_OUT_{i}_UTC0_PROT_ERR_CLR — Status ,write 1 to clear, for level_vpac_out_{i}_en_utc0_prot_err (access R/W1TC)
  [1] STATUS_LEVEL_VPAC_OUT_{i}_UTC1_ERROR_CLR — Status ,write 1 to clear, for level_vpac_out_{i}_en_utc1_error (access R/W1TC)
  [0] STATUS_LEVEL_VPAC_OUT_{i}_UTC0_ERROR_CLR — Status ,write 1 to clear, for level_vpac_out_{i}_en_utc0_error (access R/W1TC)
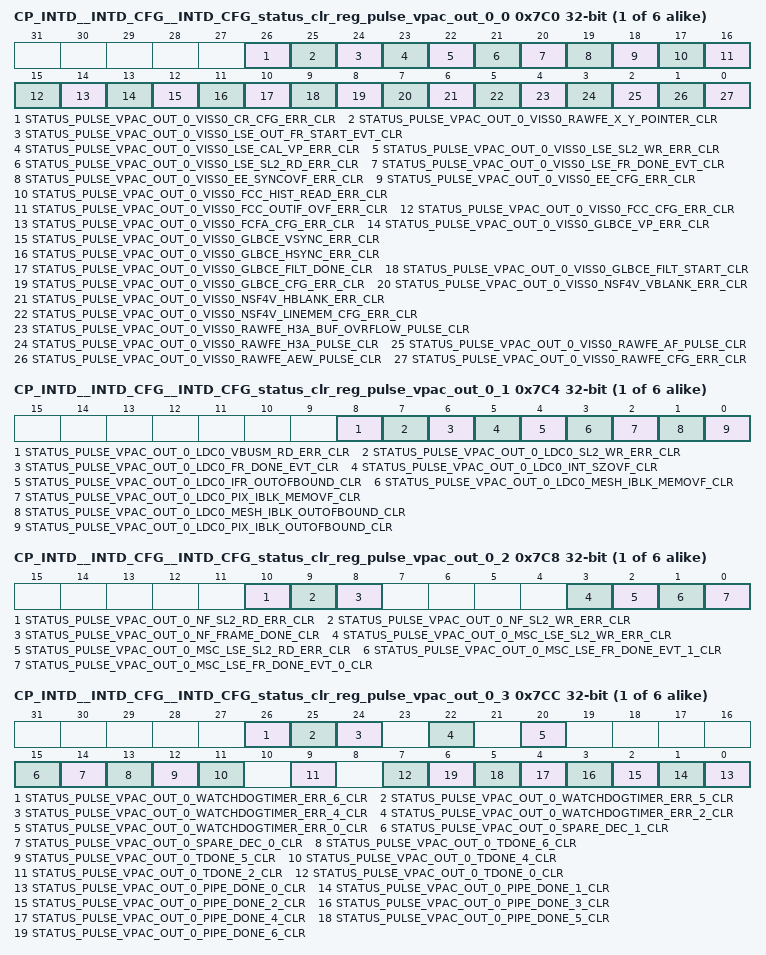
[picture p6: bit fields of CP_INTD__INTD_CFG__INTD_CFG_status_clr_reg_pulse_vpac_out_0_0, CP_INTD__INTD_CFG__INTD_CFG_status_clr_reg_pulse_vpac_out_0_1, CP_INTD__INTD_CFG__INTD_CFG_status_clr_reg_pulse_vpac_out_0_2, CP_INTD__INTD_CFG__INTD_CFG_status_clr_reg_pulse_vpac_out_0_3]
{0x7C0+0x20*i} CP_INTD__INTD_CFG__INTD_CFG_status_clr_reg_pulse_vpac_out_{i}_0 (i=0..5) — Status Clear Register {8i+48}
  [26] STATUS_PULSE_VPAC_OUT_{i}_VISS0_CR_CFG_ERR_CLR — Status ,write 1 to clear, for pulse_vpac_out_{i}_en_viss0_cr_cfg_err (access R/W1TC)
  [25] STATUS_PULSE_VPAC_OUT_{i}_VISS0_RAWFE_X_Y_POINTER_CLR — Status ,write 1 to clear, for pulse_vpac_out_{i}_en_viss0_rawfe_x_y_pointer (access R/W1TC)
  [24] STATUS_PULSE_VPAC_OUT_{i}_VISS0_LSE_OUT_FR_START_EVT_CLR — Status ,write 1 to clear, for pulse_vpac_out_{i}_en_viss0_lse_out_fr_start_evt (access R/W1TC)
  [23] STATUS_PULSE_VPAC_OUT_{i}_VISS0_LSE_CAL_VP_ERR_CLR — Status ,write 1 to clear, for pulse_vpac_out_{i}_en_viss0_lse_cal_vp_err (access R/W1TC)
  [22] STATUS_PULSE_VPAC_OUT_{i}_VISS0_LSE_SL2_WR_ERR_CLR — Status ,write 1 to clear, for pulse_vpac_out_{i}_en_viss0_lse_sl2_wr_err (access R/W1TC)
  [21] STATUS_PULSE_VPAC_OUT_{i}_VISS0_LSE_SL2_RD_ERR_CLR — Status ,write 1 to clear, for pulse_vpac_out_{i}_en_viss0_lse_sl2_rd_err (access R/W1TC)
  [20] STATUS_PULSE_VPAC_OUT_{i}_VISS0_LSE_FR_DONE_EVT_CLR — Status ,write 1 to clear, for pulse_vpac_out_{i}_en_viss0_lse_fr_done_evt (access R/W1TC)
  [19] STATUS_PULSE_VPAC_OUT_{i}_VISS0_EE_SYNCOVF_ERR_CLR — Status ,write 1 to clear, for pulse_vpac_out_{i}_en_viss0_ee_syncovf_err (access R/W1TC)
  [18] STATUS_PULSE_VPAC_OUT_{i}_VISS0_EE_CFG_ERR_CLR — Status ,write 1 to clear, for pulse_vpac_out_{i}_en_viss0_ee_cfg_err (access R/W1TC)
  [17] STATUS_PULSE_VPAC_OUT_{i}_VISS0_FCC_HIST_READ_ERR_CLR — Status ,write 1 to clear, for pulse_vpac_out_{i}_en_viss0_fcc_hist_read_err (access R/W1TC)
  [16] STATUS_PULSE_VPAC_OUT_{i}_VISS0_FCC_OUTIF_OVF_ERR_CLR — Status ,write 1 to clear, for pulse_vpac_out_{i}_en_viss0_fcc_outif_ovf_err (access R/W1TC)
  [15] STATUS_PULSE_VPAC_OUT_{i}_VISS0_FCC_CFG_ERR_CLR — Status ,write 1 to clear, for pulse_vpac_out_{i}_en_viss0_fcc_cfg_err (access R/W1TC)
  [14] STATUS_PULSE_VPAC_OUT_{i}_VISS0_FCFA_CFG_ERR_CLR — Status ,write 1 to clear, for pulse_vpac_out_{i}_en_viss0_fcfa_cfg_err (access R/W1TC)
  [13] STATUS_PULSE_VPAC_OUT_{i}_VISS0_GLBCE_VP_ERR_CLR — Status ,write 1 to clear, for pulse_vpac_out_{i}_en_viss0_glbce_vp_err (access R/W1TC)
  [12] STATUS_PULSE_VPAC_OUT_{i}_VISS0_GLBCE_VSYNC_ERR_CLR — Status ,write 1 to clear, for pulse_vpac_out_{i}_en_viss0_glbce_vsync_err (access R/W1TC)
  [11] STATUS_PULSE_VPAC_OUT_{i}_VISS0_GLBCE_HSYNC_ERR_CLR — Status ,write 1 to clear, for pulse_vpac_out_{i}_en_viss0_glbce_hsync_err (access R/W1TC)
  [10] STATUS_PULSE_VPAC_OUT_{i}_VISS0_GLBCE_FILT_DONE_CLR — Status ,write 1 to clear, for pulse_vpac_out_{i}_en_viss0_glbce_filt_done (access R/W1TC)
  [9] STATUS_PULSE_VPAC_OUT_{i}_VISS0_GLBCE_FILT_START_CLR — Status ,write 1 to clear, for pulse_vpac_out_{i}_en_viss0_glbce_filt_start (access R/W1TC)
  [8] STATUS_PULSE_VPAC_OUT_{i}_VISS0_GLBCE_CFG_ERR_CLR — Status ,write 1 to clear, for pulse_vpac_out_{i}_en_viss0_glbce_cfg_err (access R/W1TC)
  [7] STATUS_PULSE_VPAC_OUT_{i}_VISS0_NSF4V_VBLANK_ERR_CLR — Status ,write 1 to clear, for pulse_vpac_out_{i}_en_viss0_nsf4v_vblank_err (access R/W1TC)
  [6] STATUS_PULSE_VPAC_OUT_{i}_VISS0_NSF4V_HBLANK_ERR_CLR — Status ,write 1 to clear, for pulse_vpac_out_{i}_en_viss0_nsf4v_hblank_err (access R/W1TC)
  [5] STATUS_PULSE_VPAC_OUT_{i}_VISS0_NSF4V_LINEMEM_CFG_ERR_CLR — Status ,write 1 to clear, for pulse_vpac_out_{i}_en_viss0_nsf4v_linemem_cfg_err (access R/W1TC)
  [4] STATUS_PULSE_VPAC_OUT_{i}_VISS0_RAWFE_H3A_BUF_OVRFLOW_PULSE_CLR — Status ,write 1 to clear, for pulse_vpac_out_{i}_en_viss0_rawfe_h3a_buf_ovrflow_pulse (access R/W1TC)
  [3] STATUS_PULSE_VPAC_OUT_{i}_VISS0_RAWFE_H3A_PULSE_CLR — Status ,write 1 to clear, for pulse_vpac_out_{i}_en_viss0_rawfe_h3a_pulse (access R/W1TC)
  [2] STATUS_PULSE_VPAC_OUT_{i}_VISS0_RAWFE_AF_PULSE_CLR — Status ,write 1 to clear, for pulse_vpac_out_{i}_en_viss0_rawfe_af_pulse (access R/W1TC)
  [1] STATUS_PULSE_VPAC_OUT_{i}_VISS0_RAWFE_AEW_PULSE_CLR — Status ,write 1 to clear, for pulse_vpac_out_{i}_en_viss0_rawfe_aew_pulse (access R/W1TC)
  [0] STATUS_PULSE_VPAC_OUT_{i}_VISS0_RAWFE_CFG_ERR_CLR — Status ,write 1 to clear, for pulse_vpac_out_{i}_en_viss0_rawfe_cfg_err (access R/W1TC)
{0x7C4+0x20*i} CP_INTD__INTD_CFG__INTD_CFG_status_clr_reg_pulse_vpac_out_{i}_1 (i=0..5) — Status Clear Register {8i+49}
  [8] STATUS_PULSE_VPAC_OUT_{i}_LDC0_VBUSM_RD_ERR_CLR — Status ,write 1 to clear, for pulse_vpac_out_{i}_en_ldc0_vbusm_rd_err (access R/W1TC)
  [7] STATUS_PULSE_VPAC_OUT_{i}_LDC0_SL2_WR_ERR_CLR — Status ,write 1 to clear, for pulse_vpac_out_{i}_en_ldc0_sl2_wr_err (access R/W1TC)
  [6] STATUS_PULSE_VPAC_OUT_{i}_LDC0_FR_DONE_EVT_CLR — Status ,write 1 to clear, for pulse_vpac_out_{i}_en_ldc0_fr_done_evt (access R/W1TC)
  [5] STATUS_PULSE_VPAC_OUT_{i}_LDC0_INT_SZOVF_CLR — Status ,write 1 to clear, for pulse_vpac_out_{i}_en_ldc0_int_szovf (access R/W1TC)
  [4] STATUS_PULSE_VPAC_OUT_{i}_LDC0_IFR_OUTOFBOUND_CLR — Status ,write 1 to clear, for pulse_vpac_out_{i}_en_ldc0_ifr_outofbound (access R/W1TC)
  [3] STATUS_PULSE_VPAC_OUT_{i}_LDC0_MESH_IBLK_MEMOVF_CLR — Status ,write 1 to clear, for pulse_vpac_out_{i}_en_ldc0_mesh_iblk_memovf (access R/W1TC)
  [2] STATUS_PULSE_VPAC_OUT_{i}_LDC0_PIX_IBLK_MEMOVF_CLR — Status ,write 1 to clear, for pulse_vpac_out_{i}_en_ldc0_pix_iblk_memovf (access R/W1TC)
  [1] STATUS_PULSE_VPAC_OUT_{i}_LDC0_MESH_IBLK_OUTOFBOUND_CLR — Status ,write 1 to clear, for pulse_vpac_out_{i}_en_ldc0_mesh_iblk_outofbound (access R/W1TC)
  [0] STATUS_PULSE_VPAC_OUT_{i}_LDC0_PIX_IBLK_OUTOFBOUND_CLR — Status ,write 1 to clear, for pulse_vpac_out_{i}_en_ldc0_pix_iblk_outofbound (access R/W1TC)
{0x7C8+0x20*i} CP_INTD__INTD_CFG__INTD_CFG_status_clr_reg_pulse_vpac_out_{i}_2 (i=0..5) — Status Clear Register {8i+50}
  [10] STATUS_PULSE_VPAC_OUT_{i}_NF_SL2_RD_ERR_CLR — Status ,write 1 to clear, for pulse_vpac_out_{i}_en_nf_sl2_rd_err (access R/W1TC)
  [9] STATUS_PULSE_VPAC_OUT_{i}_NF_SL2_WR_ERR_CLR — Status ,write 1 to clear, for pulse_vpac_out_{i}_en_nf_sl2_wr_err (access R/W1TC)
  [8] STATUS_PULSE_VPAC_OUT_{i}_NF_FRAME_DONE_CLR — Status ,write 1 to clear, for pulse_vpac_out_{i}_en_nf_frame_done (access R/W1TC)
  [3] STATUS_PULSE_VPAC_OUT_{i}_MSC_LSE_SL2_WR_ERR_CLR — Status ,write 1 to clear, for pulse_vpac_out_{i}_en_msc_lse_sl2_wr_err (access R/W1TC)
  [2] STATUS_PULSE_VPAC_OUT_{i}_MSC_LSE_SL2_RD_ERR_CLR — Status ,write 1 to clear, for pulse_vpac_out_{i}_en_msc_lse_sl2_rd_err (access R/W1TC)
  [1] STATUS_PULSE_VPAC_OUT_{i}_MSC_LSE_FR_DONE_EVT_1_CLR — Status ,write 1 to clear, for pulse_vpac_out_{i}_en_msc_lse_fr_done_evt_1 (access R/W1TC)
  [0] STATUS_PULSE_VPAC_OUT_{i}_MSC_LSE_FR_DONE_EVT_0_CLR — Status ,write 1 to clear, for pulse_vpac_out_{i}_en_msc_lse_fr_done_evt_0 (access R/W1TC)
{0x7CC+0x20*i} CP_INTD__INTD_CFG__INTD_CFG_status_clr_reg_pulse_vpac_out_{i}_3 (i=0..5) — Status Clear Register {8i+51}
  [26] STATUS_PULSE_VPAC_OUT_{i}_WATCHDOGTIMER_ERR_6_CLR — Status ,write 1 to clear, for pulse_vpac_out_{i}_en_watchdogtimer_err_6 (access R/W1TC)
  [25] STATUS_PULSE_VPAC_OUT_{i}_WATCHDOGTIMER_ERR_5_CLR — Status ,write 1 to clear, for pulse_vpac_out_{i}_en_watchdogtimer_err_5 (access R/W1TC)
  [24] STATUS_PULSE_VPAC_OUT_{i}_WATCHDOGTIMER_ERR_4_CLR — Status ,write 1 to clear, for pulse_vpac_out_{i}_en_watchdogtimer_err_4 (access R/W1TC)
  [22] STATUS_PULSE_VPAC_OUT_{i}_WATCHDOGTIMER_ERR_2_CLR — Status ,write 1 to clear, for pulse_vpac_out_{i}_en_watchdogtimer_err_2 (access R/W1TC)
  [20] STATUS_PULSE_VPAC_OUT_{i}_WATCHDOGTIMER_ERR_0_CLR — Status ,write 1 to clear, for pulse_vpac_out_{i}_en_watchdogtimer_err_0 (access R/W1TC)
  [15] STATUS_PULSE_VPAC_OUT_{i}_SPARE_DEC_1_CLR — Status ,write 1 to clear, for pulse_vpac_out_{i}_en_spare_dec_1 (access R/W1TC)
  [14] STATUS_PULSE_VPAC_OUT_{i}_SPARE_DEC_0_CLR — Status ,write 1 to clear, for pulse_vpac_out_{i}_en_spare_dec_0 (access R/W1TC)
  [13] STATUS_PULSE_VPAC_OUT_{i}_TDONE_6_CLR — Status ,write 1 to clear, for pulse_vpac_out_{i}_en_tdone_6 (access R/W1TC)
  [12] STATUS_PULSE_VPAC_OUT_{i}_TDONE_5_CLR — Status ,write 1 to clear, for pulse_vpac_out_{i}_en_tdone_5 (access R/W1TC)
  [11] STATUS_PULSE_VPAC_OUT_{i}_TDONE_4_CLR — Status ,write 1 to clear, for pulse_vpac_out_{i}_en_tdone_4 (access R/W1TC)
  [9] STATUS_PULSE_VPAC_OUT_{i}_TDONE_2_CLR — Status ,write 1 to clear, for pulse_vpac_out_{i}_en_tdone_2 (access R/W1TC)
  [7] STATUS_PULSE_VPAC_OUT_{i}_TDONE_0_CLR — Status ,write 1 to clear, for pulse_vpac_out_{i}_en_tdone_0 (access R/W1TC)
  [n] STATUS_PULSE_VPAC_OUT_{i}_PIPE_DONE_{n}_CLR (n=0..6) — Status ,write 1 to clear, for pulse_vpac_out_{i}_en_pipe_done_{n} (access R/W1TC)
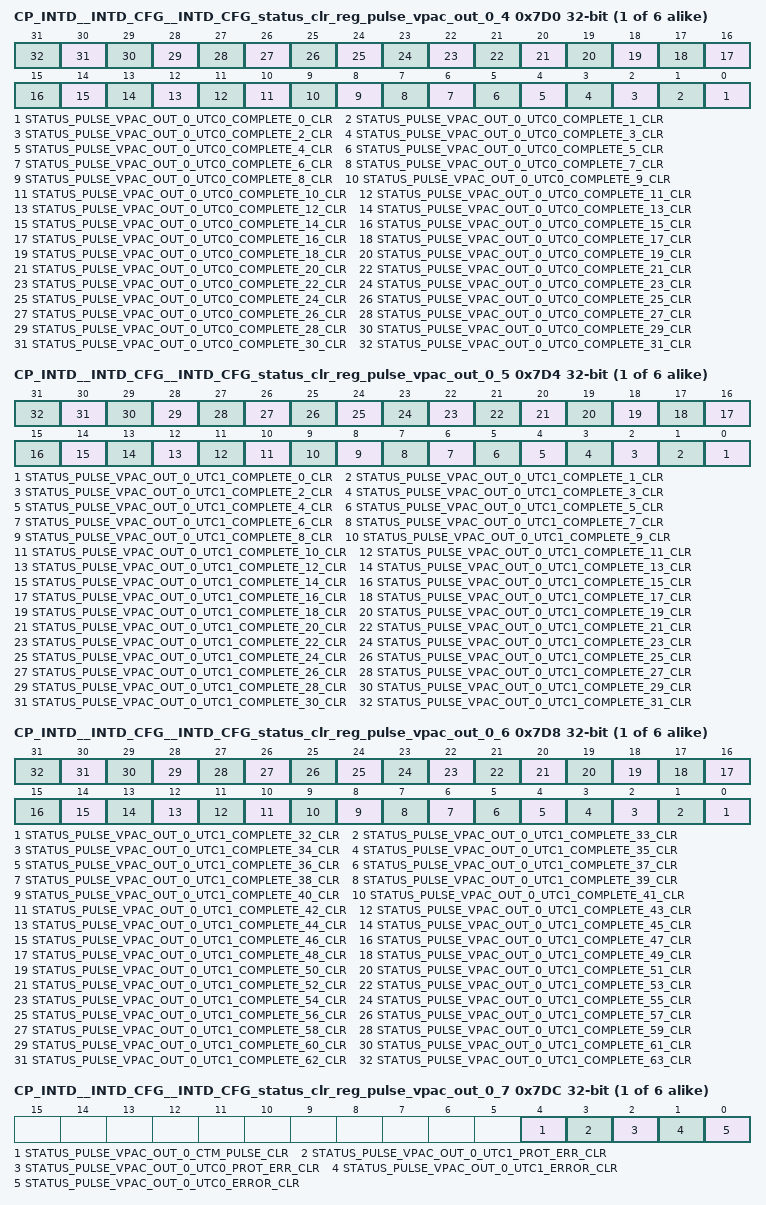
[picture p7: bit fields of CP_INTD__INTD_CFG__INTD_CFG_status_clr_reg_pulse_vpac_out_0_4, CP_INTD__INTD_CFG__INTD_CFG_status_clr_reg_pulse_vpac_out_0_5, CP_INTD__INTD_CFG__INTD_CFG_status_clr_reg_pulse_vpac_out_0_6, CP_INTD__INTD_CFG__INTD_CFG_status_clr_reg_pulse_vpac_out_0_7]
{0x7D0+0x20*i} CP_INTD__INTD_CFG__INTD_CFG_status_clr_reg_pulse_vpac_out_{i}_4 (i=0..5) — Status Clear Register {8i+52}
  [n] STATUS_PULSE_VPAC_OUT_{i}_UTC0_COMPLETE_{n}_CLR (n=0..31) — Status ,write 1 to clear, for pulse_vpac_out_{i}_en_utc0_complete_{n} (access R/W1TC)
{0x7D4+0x20*i} CP_INTD__INTD_CFG__INTD_CFG_status_clr_reg_pulse_vpac_out_{i}_5 (i=0..5) — Status Clear Register {8i+53}
  [n] STATUS_PULSE_VPAC_OUT_{i}_UTC1_COMPLETE_{n}_CLR (n=0..31) — Status ,write 1 to clear, for pulse_vpac_out_{i}_en_utc1_complete_{n} (access R/W1TC)
{0x7D8+0x20*i} CP_INTD__INTD_CFG__INTD_CFG_status_clr_reg_pulse_vpac_out_{i}_6 (i=0..5) — Status Clear Register {8i+54}
  [n-32] STATUS_PULSE_VPAC_OUT_{i}_UTC1_COMPLETE_{n}_CLR (n=32..63) — Status ,write 1 to clear, for pulse_vpac_out_{i}_en_utc1_complete_{n} (access R/W1TC)
{0x7DC+0x20*i} CP_INTD__INTD_CFG__INTD_CFG_status_clr_reg_pulse_vpac_out_{i}_7 (i=0..5) — Status Clear Register {8i+55}
  [4] STATUS_PULSE_VPAC_OUT_{i}_CTM_PULSE_CLR — Status ,write 1 to clear, for pulse_vpac_out_{i}_en_ctm_pulse (access R/W1TC)
  [3] STATUS_PULSE_VPAC_OUT_{i}_UTC1_PROT_ERR_CLR — Status ,write 1 to clear, for pulse_vpac_out_{i}_en_utc1_prot_err (access R/W1TC)
  [2] STATUS_PULSE_VPAC_OUT_{i}_UTC0_PROT_ERR_CLR — Status ,write 1 to clear, for pulse_vpac_out_{i}_en_utc0_prot_err (access R/W1TC)
  [1] STATUS_PULSE_VPAC_OUT_{i}_UTC1_ERROR_CLR — Status ,write 1 to clear, for pulse_vpac_out_{i}_en_utc1_error (access R/W1TC)
  [0] STATUS_PULSE_VPAC_OUT_{i}_UTC0_ERROR_CLR — Status ,write 1 to clear, for pulse_vpac_out_{i}_en_utc0_error (access R/W1TC)
{0xA80+4i} CP_INTD__INTD_CFG__INTD_CFG_intr_vector_reg_level_vpac_out_{i} ro (i=0..5) — Interrupt Vector for level_vpac_out_{i}
  [31:0] INTR_VECTOR_LEVEL_VPAC_OUT_{i} — Interrupt Vector
{0xA98+4i} CP_INTD__INTD_CFG__INTD_CFG_intr_vector_reg_pulse_vpac_out_{i} ro (i=0..5) — Interrupt Vector for pulse_vpac_out_{i}
  [31:0] INTR_VECTOR_PULSE_VPAC_OUT_{i} — Interrupt Vector
